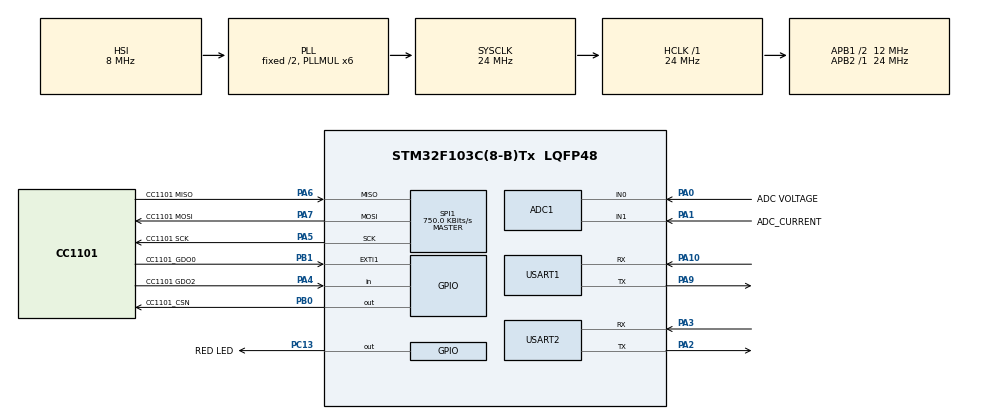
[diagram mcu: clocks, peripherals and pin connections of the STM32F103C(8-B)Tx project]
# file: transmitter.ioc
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ADC1.Channel-0\#ChannelRegularConversion=ADC_CHANNEL_0
ADC1.Channel-45\#ChannelRegularConversion=ADC_CHANNEL_1
ADC1.Channel-46\#ChannelRegularConversion=ADC_CHANNEL_0
ADC1.Channel-47\#ChannelRegularConversion=ADC_CHANNEL_0
ADC1.Channel-48\#ChannelRegularConversion=ADC_CHANNEL_0
ADC1.Channel-49\#ChannelRegularConversion=ADC_CHANNEL_0
ADC1.Channel-50\#ChannelRegularConversion=ADC_CHANNEL_0
ADC1.Channel-51\#ChannelRegularConversion=ADC_CHANNEL_0
ADC1.Channel-52\#ChannelRegularConversion=ADC_CHANNEL_0
ADC1.Channel-53\#ChannelRegularConversion=ADC_CHANNEL_0
ADC1.Channel-54\#ChannelRegularConversion=ADC_CHANNEL_0
ADC1.Channel-55\#ChannelRegularConversion=ADC_CHANNEL_0
ADC1.Channel-56\#ChannelRegularConversion=ADC_CHANNEL_0
ADC1.Channel-57\#ChannelRegularConversion=ADC_CHANNEL_0
ADC1.Channel-58\#ChannelRegularConversion=ADC_CHANNEL_0
ADC1.Channel-59\#ChannelRegularConversion=ADC_CHANNEL_0
ADC1.ContinuousConvMode=ENABLE
ADC1.DataAlign=ADC_DATAALIGN_RIGHT
ADC1.DiscontinuousConvMode=DISABLE
ADC1.EnableAnalogWatchDog=false
ADC1.EnableRegularConversion=ENABLE
ADC1.ExternalTrigConv=ADC_SOFTWARE_START
ADC1.InjNumberOfConversion=0
ADC1.NbrOfConversion=2
ADC1.NbrOfConversionFlag=1
ADC1.Rank-0\#ChannelRegularConversion=1
ADC1.Rank-45\#ChannelRegularConversion=2
ADC1.Rank-46\#ChannelRegularConversion=3
ADC1.Rank-47\#ChannelRegularConversion=4
ADC1.Rank-48\#ChannelRegularConversion=5
ADC1.Rank-49\#ChannelRegularConversion=6
ADC1.Rank-50\#ChannelRegularConversion=7
ADC1.Rank-51\#ChannelRegularConversion=8
ADC1.Rank-52\#ChannelRegularConversion=9
ADC1.Rank-53\#ChannelRegularConversion=10
ADC1.Rank-54\#ChannelRegularConversion=11
ADC1.Rank-55\#ChannelRegularConversion=12
ADC1.Rank-56\#ChannelRegularConversion=13
ADC1.Rank-57\#ChannelRegularConversion=14
ADC1.Rank-58\#ChannelRegularConversion=15
ADC1.Rank-59\#ChannelRegularConversion=16
ADC1.SamplingTime-0\#ChannelRegularConversion=ADC_SAMPLETIME_41CYCLES_5
ADC1.SamplingTime-45\#ChannelRegularConversion=ADC_SAMPLETIME_41CYCLES_5
ADC1.SamplingTime-46\#ChannelRegularConversion=ADC_SAMPLETIME_1CYCLE_5
ADC1.SamplingTime-47\#ChannelRegularConversion=ADC_SAMPLETIME_1CYCLE_5
ADC1.SamplingTime-48\#ChannelRegularConversion=ADC_SAMPLETIME_1CYCLE_5
ADC1.SamplingTime-49\#ChannelRegularConversion=ADC_SAMPLETIME_1CYCLE_5
ADC1.SamplingTime-50\#ChannelRegularConversion=ADC_SAMPLETIME_1CYCLE_5
ADC1.SamplingTime-51\#ChannelRegularConversion=ADC_SAMPLETIME_1CYCLE_5
ADC1.SamplingTime-52\#ChannelRegularConversion=ADC_SAMPLETIME_1CYCLE_5
ADC1.SamplingTime-53\#ChannelRegularConversion=ADC_SAMPLETIME_1CYCLE_5
ADC1.SamplingTime-54\#ChannelRegularConversion=ADC_SAMPLETIME_1CYCLE_5
ADC1.SamplingTime-55\#ChannelRegularConversion=ADC_SAMPLETIME_1CYCLE_5
ADC1.SamplingTime-56\#ChannelRegularConversion=ADC_SAMPLETIME_1CYCLE_5
ADC1.SamplingTime-57\#ChannelRegularConversion=ADC_SAMPLETIME_1CYCLE_5
ADC1.SamplingTime-58\#ChannelRegularConversion=ADC_SAMPLETIME_1CYCLE_5
ADC1.SamplingTime-59\#ChannelRegularConversion=ADC_SAMPLETIME_1CYCLE_5
ADC1.ScanConvMode=ADC_SCAN_ENABLE
ADC1.master=1
Dma.ADC1.0.Direction=DMA_PERIPH_TO_MEMORY
Dma.ADC1.0.Instance=DMA1_Channel1
Dma.ADC1.0.MemDataAlignment=DMA_MDATAALIGN_HALFWORD
Dma.ADC1.0.MemInc=DMA_MINC_ENABLE
Dma.ADC1.0.Mode=DMA_CIRCULAR
Dma.ADC1.0.PeriphDataAlignment=DMA_PDATAALIGN_HALFWORD
Dma.ADC1.0.PeriphInc=DMA_PINC_DISABLE
Dma.ADC1.0.Priority=DMA_PRIORITY_HIGH
Dma.Request0=ADC1
FREERTOS.INCLUDE_xTaskGetCurrentTaskHandle=1
FREERTOS.Tasks01=defaultTask,0,128,StartDefaultTask,Default,NULL
FREERTOS.configUSE_IDLE_HOOK=1
FREERTOS.configUSE_TIMERS=0
Mcu.Family=STM32F1
Mcu.Name=STM32F103C(8-B)Tx
Mcu.Package=LQFP48
NVIC.DMA1_Channel1_IRQn=true\:5\:0\:false\:false\:true\:true\:true
NVIC.EXTI1_IRQn=true\:5\:0\:false\:false\:true\:true\:true
NVIC.PriorityGroup=NVIC_PRIORITYGROUP_4
NVIC.TIM1_UP_IRQn=true\:0\:0\:false\:false\:true\:false\:true
NVIC.TimeBase=TIM1_UP_IRQn
NVIC.TimeBaseIP=TIM1
PA0-WKUP.GPIO_Label=ADC VOLTAGE
PA0-WKUP.Signal=ADCx_IN0
PA1.GPIO_Label=ADC_CURRENT
PA1.Signal=ADCx_IN1
PA10.Mode=Asynchronous
PA10.Signal=USART1_RX
PA13.Mode=Serial_Wire
PA13.Signal=SYS_JTMS-SWDIO
PA14.Mode=Serial_Wire
PA14.Signal=SYS_JTCK-SWCLK
PA2.Mode=Asynchronous
PA2.Signal=USART2_TX
PA3.Mode=Asynchronous
PA3.Signal=USART2_RX
PA4.GPIO_Label=CC1101 GDO2
PA4.Signal=GPIO_Input
PA5.GPIO_Label=CC1101 SCK
PA5.Mode=Full_Duplex_Master
PA5.Signal=SPI1_SCK
PA6.GPIO_Label=CC1101 MISO
PA6.Mode=Full_Duplex_Master
PA6.Signal=SPI1_MISO
PA7.GPIO_Label=CC1101 MOSI
PA7.Mode=Full_Duplex_Master
PA7.Signal=SPI1_MOSI
PA9.Mode=Asynchronous
PA9.Signal=USART1_TX
PB0.GPIO_Label=CC1101_CSN
PB0.Signal=GPIO_Output
PB1.GPIO_Label=CC1101_GDO0
PB1.GPIO_ModeDefaultEXTI=GPIO_MODE_IT_FALLING
PB1.Signal=GPXTI1
PC13-TAMPER-RTC.GPIO_Label=RED LED
PC13-TAMPER-RTC.Signal=GPIO_Output
PD0-OSC_IN.Signal=RCC_OSC_IN
PD1-OSC_OUT.Signal=RCC_OSC_OUT
ProjectManager.HeapSize=0x200
ProjectManager.StackSize=0x400
ProjectManager.TargetToolchain=Makefile
RCC.ADCPresc=RCC_ADCPCLK2_DIV4
RCC.AHBFreq_Value=24000000
RCC.APB1CLKDivider=RCC_HCLK_DIV2
RCC.APB1Freq_Value=12000000
RCC.APB1TimFreq_Value=24000000
RCC.APB2Freq_Value=24000000
RCC.APB2TimFreq_Value=24000000
RCC.HCLKFreq_Value=24000000
RCC.PLLMUL=RCC_PLL_MUL6
RCC.SYSCLKFreq_VALUE=24000000
RCC.SYSCLKSource=RCC_SYSCLKSOURCE_PLLCLK
RCC.USBFreq_Value=24000000
SH.ADCx_IN0.0=ADC1_IN0,IN0
SH.ADCx_IN1.0=ADC1_IN1,IN1
SPI1.BaudRatePrescaler=SPI_BAUDRATEPRESCALER_32
SPI1.CalculateBaudRate=750.0 KBits/s
SPI1.Direction=SPI_DIRECTION_2LINES
SPI1.Mode=SPI_MODE_MASTER
SPI1.VirtualType=VM_MASTER
USART1.VirtualMode=VM_ASYNC
USART2.VirtualMode=VM_ASYNC
VP_ADC1_TempSens_Input.Mode=IN-TempSens
VP_ADC1_Vref_Input.Mode=IN-Vrefint
VP_CRC_VS_CRC.Mode=CRC_Activate
VP_FREERTOS_VS_ENABLE.Mode=Enabled
VP_IWDG_VS_IWDG.Mode=IWDG_Activate
VP_SYS_VS_tim1.Mode=TIM1
board=transmitter

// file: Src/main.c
/**
  ******************************************************************************
  * @file           : main.c
  * @brief          : Main program body
  ******************************************************************************
  * This notice applies to any and all portions of this file
  * that are not between comment pairs USER CODE BEGIN and
  * USER CODE END. Other portions of this file, whether
  * inserted by the user or by software development tools
  * are owned by their respective copyright owners.
  *
  * Copyright (c) 2018 STMicroelectronics International N.V.
  * All rights reserved.
  *
  * Redistribution and use in source and binary forms, with or without
  * modification, are permitted, provided that the following conditions are met:
  *
  * 1. Redistribution of source code must retain the above copyright notice,
  *    this list of conditions and the following disclaimer.
  * 2. Redistributions in binary form must reproduce the above copyright notice,
  *    this list of conditions and the following disclaimer in the documentation
  *    and/or other materials provided with the distribution.
  * 3. Neither the name of STMicroelectronics nor the names of other
  *    contributors to this software may be used to endorse or promote products
  *    derived from this software without specific written permission.
  * 4. This software, including modifications and/or derivative works of this
  *    software, must execute solely and exclusively on microcontroller or
  *    microprocessor devices manufactured by or for STMicroelectronics.
  * 5. Redistribution and use of this software other than as permitted under
  *    this license is void and will automatically terminate your rights under
  *    this license.
  *
  * THIS SOFTWARE IS PROVIDED BY STMICROELECTRONICS AND CONTRIBUTORS "AS IS"
  * AND ANY EXPRESS, IMPLIED OR STATUTORY WARRANTIES, INCLUDING, BUT NOT
  * LIMITED TO, THE IMPLIED WARRANTIES OF MERCHANTABILITY, FITNESS FOR A
  * PARTICULAR PURPOSE AND NON-INFRINGEMENT OF THIRD PARTY INTELLECTUAL PROPERTY
  * RIGHTS ARE DISCLAIMED TO THE FULLEST EXTENT PERMITTED BY LAW. IN NO EVENT
  * SHALL STMICROELECTRONICS OR CONTRIBUTORS BE LIABLE FOR ANY DIRECT, INDIRECT,
  * INCIDENTAL, SPECIAL, EXEMPLARY, OR CONSEQUENTIAL DAMAGES (INCLUDING, BUT NOT
  * LIMITED TO, PROCUREMENT OF SUBSTITUTE GOODS OR SERVICES; LOSS OF USE, DATA,
  * OR PROFITS; OR BUSINESS INTERRUPTION) HOWEVER CAUSED AND ON ANY THEORY OF
  * LIABILITY, WHETHER IN CONTRACT, STRICT LIABILITY, OR TORT (INCLUDING
  * NEGLIGENCE OR OTHERWISE) ARISING IN ANY WAY OUT OF THE USE OF THIS SOFTWARE,
  * EVEN IF ADVISED OF THE POSSIBILITY OF SUCH DAMAGE.
  *
  ******************************************************************************
  */
#include "main.h"
#include "stm32f1xx_hal.h"
#include "cmsis_os.h"

/* USER CODE BEGIN Includes */
#include "adc/adc.h"
#include "rf/rf.h"
#include "core/core.h"
/* USER CODE END Includes */

ADC_HandleTypeDef hadc1;
DMA_HandleTypeDef hdma_adc1;

CRC_HandleTypeDef hcrc;

IWDG_HandleTypeDef hiwdg;

SPI_HandleTypeDef hspi1;

UART_HandleTypeDef huart1;
UART_HandleTypeDef huart2;

osThreadId defaultTaskHandle;

/* USER CODE BEGIN PV */
/* Private variables ---------------------------------------------------------*/

/* USER CODE END PV */

void SystemClock_Config(void);
static void MX_GPIO_Init(void);
static void MX_DMA_Init(void);
static void MX_ADC1_Init(void);
static void MX_CRC_Init(void);
static void MX_IWDG_Init(void);
static void MX_SPI1_Init(void);
static void MX_USART1_UART_Init(void);
static void MX_USART2_UART_Init(void);
void StartDefaultTask(void const * argument);

/* USER CODE BEGIN PFP */
/* Private function prototypes -----------------------------------------------*/

/* USER CODE END PFP */

int main(void)
{

  /* MCU Configuration----------------------------------------------------------*/

  /* Reset of all peripherals, Initializes the Flash interface and the Systick. */
  HAL_Init();

  /* Configure the system clock */
  SystemClock_Config();

  /* Initialize all configured peripherals */
  MX_GPIO_Init();
  MX_DMA_Init();
  MX_ADC1_Init();
  MX_CRC_Init();
  MX_IWDG_Init();
  MX_SPI1_Init();
  MX_USART1_UART_Init();
  MX_USART2_UART_Init();
  /* USER CODE BEGIN 2 */
  rf_init();
  adc_init(&hadc1);
  core_init();
  /* USER CODE END 2 */

  /* Create the thread(s) */
  /* definition and creation of defaultTask */
  osThreadDef(defaultTask, StartDefaultTask, osPriorityNormal, 0, 128);
  defaultTaskHandle = osThreadCreate(osThread(defaultTask), NULL);

  /* Start scheduler */
  osKernelStart();

  /* We should never get here as control is now taken by the scheduler */

  /* Infinite loop */
  while (1)
  {

  }

}

void SystemClock_Config(void)
{

  RCC_OscInitTypeDef RCC_OscInitStruct;
  RCC_ClkInitTypeDef RCC_ClkInitStruct;
  RCC_PeriphCLKInitTypeDef PeriphClkInit;

    /**Initializes the CPU, AHB and APB busses clocks
    */
  RCC_OscInitStruct.OscillatorType = RCC_OSCILLATORTYPE_HSI|RCC_OSCILLATORTYPE_LSI;
  RCC_OscInitStruct.HSIState = RCC_HSI_ON;
  RCC_OscInitStruct.HSICalibrationValue = 16;
  RCC_OscInitStruct.LSIState = RCC_LSI_ON;
  RCC_OscInitStruct.PLL.PLLState = RCC_PLL_ON;
  RCC_OscInitStruct.PLL.PLLSource = RCC_PLLSOURCE_HSI_DIV2;
  RCC_OscInitStruct.PLL.PLLMUL = RCC_PLL_MUL6;
  if (HAL_RCC_OscConfig(&RCC_OscInitStruct) != HAL_OK)
  {
    _Error_Handler(__FILE__, __LINE__);
  }

    /**Initializes the CPU, AHB and APB busses clocks
    */
  RCC_ClkInitStruct.ClockType = RCC_CLOCKTYPE_HCLK|RCC_CLOCKTYPE_SYSCLK
                              |RCC_CLOCKTYPE_PCLK1|RCC_CLOCKTYPE_PCLK2;
  RCC_ClkInitStruct.SYSCLKSource = RCC_SYSCLKSOURCE_PLLCLK;
  RCC_ClkInitStruct.AHBCLKDivider = RCC_SYSCLK_DIV1;
  RCC_ClkInitStruct.APB1CLKDivider = RCC_HCLK_DIV2;
  RCC_ClkInitStruct.APB2CLKDivider = RCC_HCLK_DIV1;

  if (HAL_RCC_ClockConfig(&RCC_ClkInitStruct, FLASH_LATENCY_0) != HAL_OK)
  {
    _Error_Handler(__FILE__, __LINE__);
  }

  PeriphClkInit.PeriphClockSelection = RCC_PERIPHCLK_ADC;
  PeriphClkInit.AdcClockSelection = RCC_ADCPCLK2_DIV4;
  if (HAL_RCCEx_PeriphCLKConfig(&PeriphClkInit) != HAL_OK)
  {
    _Error_Handler(__FILE__, __LINE__);
  }

    /**Configure the Systick interrupt time
    */
  HAL_SYSTICK_Config(HAL_RCC_GetHCLKFreq()/1000);

    /**Configure the Systick
    */
  HAL_SYSTICK_CLKSourceConfig(SYSTICK_CLKSOURCE_HCLK);

  /* SysTick_IRQn interrupt configuration */
  HAL_NVIC_SetPriority(SysTick_IRQn, 15, 0);
}

/* ADC1 init function */
static void MX_ADC1_Init(void)
{

  ADC_ChannelConfTypeDef sConfig;

    /**Common config
    */
  hadc1.Instance = ADC1;
  hadc1.Init.ScanConvMode = ADC_SCAN_ENABLE;
  hadc1.Init.ContinuousConvMode = ENABLE;
  hadc1.Init.DiscontinuousConvMode = DISABLE;
  hadc1.Init.ExternalTrigConv = ADC_SOFTWARE_START;
  hadc1.Init.DataAlign = ADC_DATAALIGN_RIGHT;
  hadc1.Init.NbrOfConversion = 2;
  if (HAL_ADC_Init(&hadc1) != HAL_OK)
  {
    _Error_Handler(__FILE__, __LINE__);
  }

    /**Configure Regular Channel
    */
  sConfig.Channel = ADC_CHANNEL_0;
  sConfig.Rank = ADC_REGULAR_RANK_1;
  sConfig.SamplingTime = ADC_SAMPLETIME_41CYCLES_5;
  if (HAL_ADC_ConfigChannel(&hadc1, &sConfig) != HAL_OK)
  {
    _Error_Handler(__FILE__, __LINE__);
  }

    /**Configure Regular Channel
    */
  sConfig.Channel = ADC_CHANNEL_1;
  sConfig.Rank = ADC_REGULAR_RANK_2;
  if (HAL_ADC_ConfigChannel(&hadc1, &sConfig) != HAL_OK)
  {
    _Error_Handler(__FILE__, __LINE__);
  }

}

/* CRC init function */
static void MX_CRC_Init(void)
{

  hcrc.Instance = CRC;
  if (HAL_CRC_Init(&hcrc) != HAL_OK)
  {
    _Error_Handler(__FILE__, __LINE__);
  }

}

/* IWDG init function */
static void MX_IWDG_Init(void)
{

  hiwdg.Instance = IWDG;
  hiwdg.Init.Prescaler = IWDG_PRESCALER_4;
  hiwdg.Init.Reload = 4095;
  if (HAL_IWDG_Init(&hiwdg) != HAL_OK)
  {
    _Error_Handler(__FILE__, __LINE__);
  }

}

/* SPI1 init function */
static void MX_SPI1_Init(void)
{

  /* SPI1 parameter configuration*/
  hspi1.Instance = SPI1;
  hspi1.Init.Mode = SPI_MODE_MASTER;
  hspi1.Init.Direction = SPI_DIRECTION_2LINES;
  hspi1.Init.DataSize = SPI_DATASIZE_8BIT;
  hspi1.Init.CLKPolarity = SPI_POLARITY_LOW;
  hspi1.Init.CLKPhase = SPI_PHASE_1EDGE;
  hspi1.Init.NSS = SPI_NSS_SOFT;
  hspi1.Init.BaudRatePrescaler = SPI_BAUDRATEPRESCALER_32;
  hspi1.Init.FirstBit = SPI_FIRSTBIT_MSB;
  hspi1.Init.TIMode = SPI_TIMODE_DISABLE;
  hspi1.Init.CRCCalculation = SPI_CRCCALCULATION_DISABLE;
  hspi1.Init.CRCPolynomial = 10;
  if (HAL_SPI_Init(&hspi1) != HAL_OK)
  {
    _Error_Handler(__FILE__, __LINE__);
  }

}

/* USART1 init function */
static void MX_USART1_UART_Init(void)
{

  huart1.Instance = USART1;
  huart1.Init.BaudRate = 115200;
  huart1.Init.WordLength = UART_WORDLENGTH_8B;
  huart1.Init.StopBits = UART_STOPBITS_1;
  huart1.Init.Parity = UART_PARITY_NONE;
  huart1.Init.Mode = UART_MODE_TX_RX;
  huart1.Init.HwFlowCtl = UART_HWCONTROL_NONE;
  huart1.Init.OverSampling = UART_OVERSAMPLING_16;
  if (HAL_UART_Init(&huart1) != HAL_OK)
  {
    _Error_Handler(__FILE__, __LINE__);
  }

}

/* USART2 init function */
static void MX_USART2_UART_Init(void)
{

  huart2.Instance = USART2;
  huart2.Init.BaudRate = 115200;
  huart2.Init.WordLength = UART_WORDLENGTH_8B;
  huart2.Init.StopBits = UART_STOPBITS_1;
  huart2.Init.Parity = UART_PARITY_NONE;
  huart2.Init.Mode = UART_MODE_TX_RX;
  huart2.Init.HwFlowCtl = UART_HWCONTROL_NONE;
  huart2.Init.OverSampling = UART_OVERSAMPLING_16;
  if (HAL_UART_Init(&huart2) != HAL_OK)
  {
    _Error_Handler(__FILE__, __LINE__);
  }

}

static void MX_DMA_Init(void)
{
  /* DMA controller clock enable */
  __HAL_RCC_DMA1_CLK_ENABLE();

  /* DMA interrupt init */
  /* DMA1_Channel1_IRQn interrupt configuration */
  HAL_NVIC_SetPriority(DMA1_Channel1_IRQn, 5, 0);
  HAL_NVIC_EnableIRQ(DMA1_Channel1_IRQn);

}

/** Configure pins as
        * Analog
        * Input
        * Output
        * EVENT_OUT
        * EXTI
*/
static void MX_GPIO_Init(void)
{

  GPIO_InitTypeDef GPIO_InitStruct;

  /* GPIO Ports Clock Enable */
  __HAL_RCC_GPIOC_CLK_ENABLE();
  __HAL_RCC_GPIOD_CLK_ENABLE();
  __HAL_RCC_GPIOA_CLK_ENABLE();
  __HAL_RCC_GPIOB_CLK_ENABLE();

  /*Configure GPIO pin Output Level */
  HAL_GPIO_WritePin(RED_LED_GPIO_Port, RED_LED_Pin, GPIO_PIN_RESET);

  /*Configure GPIO pin Output Level */
  HAL_GPIO_WritePin(CC1101_CSN_GPIO_Port, CC1101_CSN_Pin, GPIO_PIN_RESET);

  /*Configure GPIO pin : RED_LED_Pin */
  GPIO_InitStruct.Pin = RED_LED_Pin;
  GPIO_InitStruct.Mode = GPIO_MODE_OUTPUT_PP;
  GPIO_InitStruct.Pull = GPIO_NOPULL;
  GPIO_InitStruct.Speed = GPIO_SPEED_FREQ_LOW;
  HAL_GPIO_Init(RED_LED_GPIO_Port, &GPIO_InitStruct);

  /*Configure GPIO pin : CC1101_GDO2_Pin */
  GPIO_InitStruct.Pin = CC1101_GDO2_Pin;
  GPIO_InitStruct.Mode = GPIO_MODE_INPUT;
  GPIO_InitStruct.Pull = GPIO_NOPULL;
  HAL_GPIO_Init(CC1101_GDO2_GPIO_Port, &GPIO_InitStruct);

  /*Configure GPIO pin : CC1101_CSN_Pin */
  GPIO_InitStruct.Pin = CC1101_CSN_Pin;
  GPIO_InitStruct.Mode = GPIO_MODE_OUTPUT_PP;
  GPIO_InitStruct.Pull = GPIO_NOPULL;
  GPIO_InitStruct.Speed = GPIO_SPEED_FREQ_LOW;
  HAL_GPIO_Init(CC1101_CSN_GPIO_Port, &GPIO_InitStruct);

  /*Configure GPIO pin : CC1101_GDO0_Pin */
  GPIO_InitStruct.Pin = CC1101_GDO0_Pin;
  GPIO_InitStruct.Mode = GPIO_MODE_IT_FALLING;
  GPIO_InitStruct.Pull = GPIO_NOPULL;
  HAL_GPIO_Init(CC1101_GDO0_GPIO_Port, &GPIO_InitStruct);

  /* EXTI interrupt init*/
  HAL_NVIC_SetPriority(EXTI1_IRQn, 5, 0);
  HAL_NVIC_EnableIRQ(EXTI1_IRQn);

}

/* USER CODE BEGIN 4 */
void vApplicationIdleHook(void) {
  HAL_IWDG_Refresh(&hiwdg);
}
/* USER CODE END 4 */

void StartDefaultTask(void const * argument)
{

  /* USER CODE BEGIN 5 */

  /* Infinite loop */
  while(true) {
    osDelay(300);

    /*uint8_t data[32] = { 0 };
    ADC_Voltage volts = adc_voltage_read();
    //volts.integer = 22;
    //volts.fractional = 1234;
    data[0] = 'Q';//device_id();
    data[1] = (uint8_t)volts.integer;
    data[2] = (uint8_t)(volts.fractional >> 8);
    data[3] = (uint8_t)volts.fractional;
    rf_transmit(data);
*/
  //  char *buf = "hello";
  //  rf_transmit((const uint8_t *)buf);

    //HAL_GPIO_TogglePin(GPIOC, GPIO_PIN_13);

    //CDC_Transmit_FS((uint8_t *)get_buf(), 32);
    //const uint8_t *str = "hello world\n";

  }
  /* USER CODE END 5 */
}

void HAL_TIM_PeriodElapsedCallback(TIM_HandleTypeDef *htim)
{
  if (htim->Instance == TIM1) {
    HAL_IncTick();
  }
}

void _Error_Handler(char *file, int line)
{
  /* USER CODE BEGIN Error_Handler_Debug */
  /* User can add his own implementation to report the HAL error return state */
  printf("HAL error in file %s on line %d\n", file, line);
  while(1)
  {
  }
  /* USER CODE END Error_Handler_Debug */
}

#ifdef  USE_FULL_ASSERT
/**
  * @brief  Reports the name of the source file and the source line number
  *         where the assert_param error has occurred.
  * @param  file: pointer to the source file name
  * @param  line: assert_param error line source number
  * @retval None
  */
void assert_failed(uint8_t* file, uint32_t line)
{
  /* USER CODE BEGIN 6 */
  /* User can add his own implementation to report the file name and line number,
    ex: printf("Wrong parameters value: file %s on line %d\r\n", file, line) */
    printf("Assert failed in file %s on line %lu\n", file, line);
  /* USER CODE END 6 */
}
#endif /* USE_FULL_ASSERT */

/************************ (C) COPYRIGHT STMicroelectronics *****END OF FILE****/

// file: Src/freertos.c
/* USER CODE BEGIN Header */
/**
  ******************************************************************************
  * File Name          : freertos.c
  * Description        : Code for freertos applications
  ******************************************************************************
  * This notice applies to any and all portions of this file
  * that are not between comment pairs USER CODE BEGIN and
  * USER CODE END. Other portions of this file, whether
  * inserted by the user or by software development tools
  * are owned by their respective copyright owners.
  *
  * Copyright (c) 2018 STMicroelectronics International N.V.
  * All rights reserved.
  *
  * Redistribution and use in source and binary forms, with or without
  * modification, are permitted, provided that the following conditions are met:
  *
  * 1. Redistribution of source code must retain the above copyright notice,
  *    this list of conditions and the following disclaimer.
  * 2. Redistributions in binary form must reproduce the above copyright notice,
  *    this list of conditions and the following disclaimer in the documentation
  *    and/or other materials provided with the distribution.
  * 3. Neither the name of STMicroelectronics nor the names of other
  *    contributors to this software may be used to endorse or promote products
  *    derived from this software without specific written permission.
  * 4. This software, including modifications and/or derivative works of this
  *    software, must execute solely and exclusively on microcontroller or
  *    microprocessor devices manufactured by or for STMicroelectronics.
  * 5. Redistribution and use of this software other than as permitted under
  *    this license is void and will automatically terminate your rights under
  *    this license.
  *
  * THIS SOFTWARE IS PROVIDED BY STMICROELECTRONICS AND CONTRIBUTORS "AS IS"
  * AND ANY EXPRESS, IMPLIED OR STATUTORY WARRANTIES, INCLUDING, BUT NOT
  * LIMITED TO, THE IMPLIED WARRANTIES OF MERCHANTABILITY, FITNESS FOR A
  * PARTICULAR PURPOSE AND NON-INFRINGEMENT OF THIRD PARTY INTELLECTUAL PROPERTY
  * RIGHTS ARE DISCLAIMED TO THE FULLEST EXTENT PERMITTED BY LAW. IN NO EVENT
  * SHALL STMICROELECTRONICS OR CONTRIBUTORS BE LIABLE FOR ANY DIRECT, INDIRECT,
  * INCIDENTAL, SPECIAL, EXEMPLARY, OR CONSEQUENTIAL DAMAGES (INCLUDING, BUT NOT
  * LIMITED TO, PROCUREMENT OF SUBSTITUTE GOODS OR SERVICES; LOSS OF USE, DATA,
  * OR PROFITS; OR BUSINESS INTERRUPTION) HOWEVER CAUSED AND ON ANY THEORY OF
  * LIABILITY, WHETHER IN CONTRACT, STRICT LIABILITY, OR TORT (INCLUDING
  * NEGLIGENCE OR OTHERWISE) ARISING IN ANY WAY OUT OF THE USE OF THIS SOFTWARE,
  * EVEN IF ADVISED OF THE POSSIBILITY OF SUCH DAMAGE.
  *
  ******************************************************************************
  */
/* USER CODE END Header */

#include "FreeRTOS.h"
#include "task.h"
#include "main.h"

/* USER CODE BEGIN Includes */
#include "stm32f1xx_hal.h"
/* USER CODE END Includes */

/* Hook prototypes */
void vApplicationIdleHook(void);

/* USER CODE BEGIN 2 */
__weak void vApplicationIdleHook( void )
{
   /* vApplicationIdleHook() will only be called if configUSE_IDLE_HOOK is set
   to 1 in FreeRTOSConfig.h. It will be called on each iteration of the idle
   task. It is essential that code added to this hook function never attempts
   to block in any way (for example, call xQueueReceive() with a block time
   specified, or call vTaskDelay()). If the application makes use of the
   vTaskDelete() API function (as this demo application does) then it is also
   important that vApplicationIdleHook() is permitted to return to its calling
   function, because it is the responsibility of the idle task to clean up
   memory allocated by the kernel to any task that has since been deleted. */
}
/* USER CODE END 2 */

/************************ (C) COPYRIGHT STMicroelectronics *****END OF FILE****/
